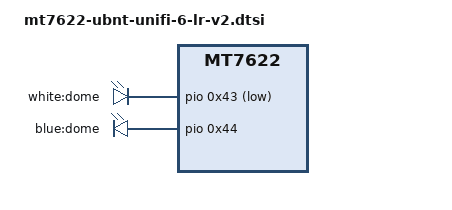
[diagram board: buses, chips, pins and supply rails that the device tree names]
#include "mt7622-ubnt-unifi-6-lr.dtsi"

/ {
	aliases {
		led-boot = &led_white;
		led-failsafe = &led_white;
		led-running = &led_blue;
		led-upgrade = &led_blue;
	};

	gpio-leds {
		compatible = "gpio-leds";

		led_white: dome_white {
			label = "white:dome";
			gpios = <&pio 0x43 GPIO_ACTIVE_LOW>;
		};

		led_blue: dome_blue {
			label = "blue:dome";
			gpios = <&pio 0x44 GPIO_ACTIVE_HIGH>;
		};
	};
};
